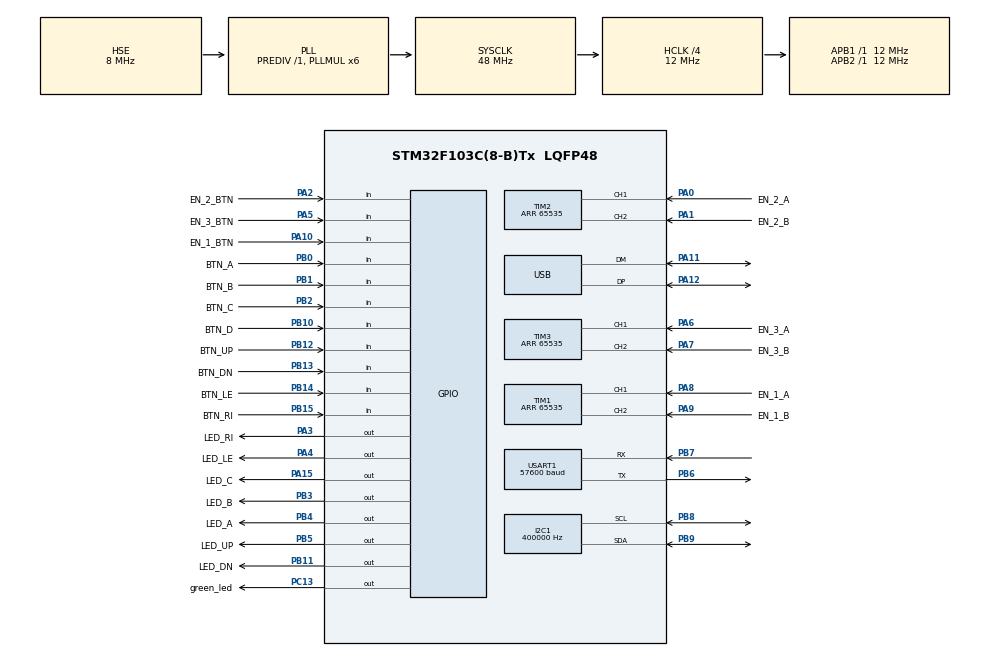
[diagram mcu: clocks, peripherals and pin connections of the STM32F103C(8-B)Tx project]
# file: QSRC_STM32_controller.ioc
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I2C1.ClockSpeed=400000
I2C1.DutyCycle=I2C_DUTYCYCLE_2
I2C1.I2C_Mode=I2C_Fast
Mcu.Family=STM32F1
Mcu.Name=STM32F103C(8-B)Tx
Mcu.Package=LQFP48
NVIC.PriorityGroup=NVIC_PRIORITYGROUP_4
NVIC.RTC_IRQn=true\:0\:0\:false\:false\:true\:true\:true
NVIC.TIM4_IRQn=true\:0\:0\:false\:false\:true\:true\:true
NVIC.USART1_IRQn=true\:0\:0\:false\:false\:true\:true\:true
NVIC.USB_LP_CAN1_RX0_IRQn=true\:0\:0\:false\:false\:true\:true\:true
PA0-WKUP.GPIO_Label=EN_2_A
PA0-WKUP.GPIO_PuPd=GPIO_PULLUP
PA0-WKUP.Signal=S_TIM2_CH1_ETR
PA1.GPIO_Label=EN_2_B
PA1.GPIO_PuPd=GPIO_PULLUP
PA1.Signal=S_TIM2_CH2
PA10.GPIO_Label=EN_1_BTN
PA10.GPIO_PuPd=GPIO_PULLUP
PA10.Signal=GPIO_Input
PA11.Mode=Device
PA11.Signal=USB_DM
PA12.Mode=Device
PA12.Signal=USB_DP
PA13.Mode=Serial_Wire
PA13.Signal=SYS_JTMS-SWDIO
PA14.Mode=Serial_Wire
PA14.Signal=SYS_JTCK-SWCLK
PA15.GPIO_Label=LED_C
PA15.Signal=GPIO_Output
PA2.GPIO_Label=EN_2_BTN
PA2.GPIO_PuPd=GPIO_PULLUP
PA2.Signal=GPIO_Input
PA3.GPIO_Label=LED_RI
PA3.PinState=GPIO_PIN_RESET
PA3.Signal=GPIO_Output
PA4.GPIO_Label=LED_LE
PA4.Signal=GPIO_Output
PA5.GPIO_Label=EN_3_BTN
PA5.GPIO_PuPd=GPIO_PULLUP
PA5.Signal=GPIO_Input
PA6.GPIO_Label=EN_3_A
PA6.GPIO_PuPd=GPIO_PULLUP
PA6.Signal=S_TIM3_CH1
PA7.GPIO_Label=EN_3_B
PA7.GPIO_PuPd=GPIO_PULLUP
PA7.Signal=S_TIM3_CH2
PA8.GPIO_Label=EN_1_A
PA8.GPIO_PuPd=GPIO_PULLUP
PA8.Signal=S_TIM1_CH1
PA9.GPIO_Label=EN_1_B
PA9.GPIO_PuPd=GPIO_PULLUP
PA9.Signal=S_TIM1_CH2
PB0.GPIO_Label=BTN_A
PB0.GPIO_PuPd=GPIO_PULLUP
PB0.Signal=GPIO_Input
PB1.GPIO_Label=BTN_B
PB1.GPIO_PuPd=GPIO_PULLUP
PB1.Signal=GPIO_Input
PB10.GPIO_Label=BTN_D
PB10.GPIO_PuPd=GPIO_PULLUP
PB10.Signal=GPIO_Input
PB11.GPIO_Label=LED_DN
PB11.Signal=GPIO_Output
PB12.GPIO_Label=BTN_UP
PB12.GPIO_PuPd=GPIO_PULLUP
PB12.Signal=GPIO_Input
PB13.GPIO_Label=BTN_DN
PB13.GPIO_PuPd=GPIO_PULLUP
PB13.Signal=GPIO_Input
PB14.GPIO_Label=BTN_LE
PB14.GPIO_PuPd=GPIO_PULLUP
PB14.Signal=GPIO_Input
PB15.GPIO_Label=BTN_RI
PB15.GPIO_PuPd=GPIO_PULLUP
PB15.Signal=GPIO_Input
PB2.GPIO_Label=BTN_C
PB2.GPIO_PuPd=GPIO_PULLUP
PB2.Signal=GPIO_Input
PB3.GPIO_Label=LED_B
PB3.Signal=GPIO_Output
PB4.GPIO_Label=LED_A
PB4.Signal=GPIO_Output
PB5.GPIO_Label=LED_UP
PB5.Signal=GPIO_Output
PB6.Mode=Asynchronous
PB6.Signal=USART1_TX
PB7.Mode=Asynchronous
PB7.Signal=USART1_RX
PB8.Mode=I2C
PB8.Signal=I2C1_SCL
PB9.Mode=I2C
PB9.Signal=I2C1_SDA
PC13-TAMPER-RTC.GPIO_Label=green_led
PC13-TAMPER-RTC.GPIO_Speed=GPIO_SPEED_FREQ_LOW
PC13-TAMPER-RTC.PinState=GPIO_PIN_SET
PC13-TAMPER-RTC.Signal=GPIO_Output
PC14-OSC32_IN.Mode=LSE-External-Oscillator
PC14-OSC32_IN.Signal=RCC_OSC32_IN
PC15-OSC32_OUT.Mode=LSE-External-Oscillator
PC15-OSC32_OUT.Signal=RCC_OSC32_OUT
PD0-OSC_IN.Mode=HSE-External-Oscillator
PD0-OSC_IN.Signal=RCC_OSC_IN
PD1-OSC_OUT.Mode=HSE-External-Oscillator
PD1-OSC_OUT.Signal=RCC_OSC_OUT
ProjectManager.HeapSize=0x200
ProjectManager.StackSize=0x400
ProjectManager.TargetToolchain=STM32CubeIDE
RCC.AHBCLKDivider=RCC_SYSCLK_DIV4
RCC.AHBFreq_Value=12000000
RCC.APB1Freq_Value=12000000
RCC.APB1TimFreq_Value=12000000
RCC.APB2Freq_Value=12000000
RCC.APB2TimFreq_Value=12000000
RCC.HCLKFreq_Value=12000000
RCC.PLLMUL=RCC_PLL_MUL6
RCC.SYSCLKFreq_VALUE=48000000
RCC.SYSCLKSource=RCC_SYSCLKSOURCE_PLLCLK
RCC.USBFreq_Value=48000000
SH.S_TIM1_CH1.0=TIM1_CH1,Encoder_Interface
SH.S_TIM1_CH2.0=TIM1_CH2,Encoder_Interface
SH.S_TIM2_CH1_ETR.0=TIM2_CH1,Encoder_Interface
SH.S_TIM2_CH2.0=TIM2_CH2,Encoder_Interface
SH.S_TIM3_CH1.0=TIM3_CH1,Encoder_Interface
SH.S_TIM3_CH2.0=TIM3_CH2,Encoder_Interface
TIM1.CounterMode=TIM_COUNTERMODE_DOWN
TIM1.EncoderMode=TIM_ENCODERMODE_TI12
TIM1.IC1Filter=15
TIM1.IC1Polarity=TIM_ICPOLARITY_FALLING
TIM1.IC2Filter=15
TIM1.Period=65535
TIM2.CounterMode=TIM_COUNTERMODE_DOWN
TIM2.EncoderMode=TIM_ENCODERMODE_TI12
TIM2.IC1Filter=15
TIM2.IC1Polarity=TIM_ICPOLARITY_FALLING
TIM2.IC2Filter=15
TIM2.Period=65535
TIM3.CounterMode=TIM_COUNTERMODE_DOWN
TIM3.EncoderMode=TIM_ENCODERMODE_TI12
TIM3.IC1Filter=15
TIM3.IC1Polarity=TIM_ICPOLARITY_FALLING
TIM3.IC2Filter=15
TIM3.IC2Polarity=TIM_ICPOLARITY_FALLING
TIM3.Period=65535
USART1.BaudRate=57600
USART1.VirtualMode=VM_ASYNC
USB_DEVICE.CLASS_NAME_FS=CDC
USB_DEVICE.PRODUCT_STRING_CDC_FS=QSRC
USB_DEVICE.SERIALNUMBER_STRING_CDC_FS=1A
USB_DEVICE.USBD_SUPPORT_USER_STRING-CDC_FS=0
USB_DEVICE.VirtualMode=Cdc
USB_DEVICE.VirtualModeFS=Cdc_FS
VP_RTC_No_RTC_Output.Mode=RTC_OUT_NO
VP_RTC_VS_RTC_Activate.Mode=RTC_Enabled
VP_TIM4_VS_ClockSourceINT.Mode=Internal
VP_USB_DEVICE_VS_USB_DEVICE_CDC_FS.Mode=CDC_FS
board=QSRC_STM32_controller

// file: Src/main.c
/* USER CODE BEGIN Header */
/**
  ******************************************************************************
  * @file           : main.c
  * @brief          : Main program body
  ******************************************************************************
  * @attention
  *
  * <h2><center>&copy; Copyright (c) 2022 STMicroelectronics.
  * All rights reserved.</center></h2>
  *
  * This software component is licensed by ST under Ultimate Liberty license
  * SLA0044, the "License"; You may not use this file except in compliance with
  * the License. You may obtain a copy of the License at:
  *                             www.st.com/SLA0044
  *
  ******************************************************************************
  */
/* USER CODE END Header */

#include "main.h"
#include "i2c.h"
#include "rtc.h"
#include "tim.h"
#include "usart.h"
#include "usb_device.h"
#include "gpio.h"

/* USER CODE BEGIN Includes */
#include "startup.h"
/* USER CODE END Includes */

/* USER CODE BEGIN PV */
/* Private variables ---------------------------------------------------------*/

/* USER CODE END PV */

void SystemClock_Config(void);
/* USER CODE BEGIN PFP */
/* Private function prototypes -----------------------------------------------*/

/* USER CODE END PFP */

int main(void)
{

  /* MCU Configuration--------------------------------------------------------*/

  /* Reset of all peripherals, Initializes the Flash interface and the Systick. */
  HAL_Init();

  /* Configure the system clock */
  SystemClock_Config();

  /* Initialize all configured peripherals */
  MX_GPIO_Init();
  MX_I2C1_Init();
  MX_RTC_Init();
  MX_TIM1_Init();
  MX_TIM2_Init();
  MX_TIM3_Init();
  MX_TIM4_Init();
  MX_USART1_UART_Init();
  MX_USB_DEVICE_Init();
  /* USER CODE BEGIN 2 */
  startup();
  /* USER CODE END 2 */

  /* Infinite loop */
  while (1)
  {

  }
}

void SystemClock_Config(void)
{
  RCC_OscInitTypeDef RCC_OscInitStruct = {0};
  RCC_ClkInitTypeDef RCC_ClkInitStruct = {0};
  RCC_PeriphCLKInitTypeDef PeriphClkInit = {0};

  /** Initializes the CPU, AHB and APB busses clocks
  */
  RCC_OscInitStruct.OscillatorType = RCC_OSCILLATORTYPE_LSI|RCC_OSCILLATORTYPE_HSE;
  RCC_OscInitStruct.HSEState = RCC_HSE_ON;
  RCC_OscInitStruct.HSEPredivValue = RCC_HSE_PREDIV_DIV1;
  RCC_OscInitStruct.HSIState = RCC_HSI_ON;
  RCC_OscInitStruct.LSIState = RCC_LSI_ON;
  RCC_OscInitStruct.PLL.PLLState = RCC_PLL_ON;
  RCC_OscInitStruct.PLL.PLLSource = RCC_PLLSOURCE_HSE;
  RCC_OscInitStruct.PLL.PLLMUL = RCC_PLL_MUL6;
  if (HAL_RCC_OscConfig(&RCC_OscInitStruct) != HAL_OK)
  {
    Error_Handler();
  }
  /** Initializes the CPU, AHB and APB busses clocks
  */
  RCC_ClkInitStruct.ClockType = RCC_CLOCKTYPE_HCLK|RCC_CLOCKTYPE_SYSCLK
                              |RCC_CLOCKTYPE_PCLK1|RCC_CLOCKTYPE_PCLK2;
  RCC_ClkInitStruct.SYSCLKSource = RCC_SYSCLKSOURCE_PLLCLK;
  RCC_ClkInitStruct.AHBCLKDivider = RCC_SYSCLK_DIV4;
  RCC_ClkInitStruct.APB1CLKDivider = RCC_HCLK_DIV1;
  RCC_ClkInitStruct.APB2CLKDivider = RCC_HCLK_DIV1;

  if (HAL_RCC_ClockConfig(&RCC_ClkInitStruct, FLASH_LATENCY_1) != HAL_OK)
  {
    Error_Handler();
  }
  PeriphClkInit.PeriphClockSelection = RCC_PERIPHCLK_RTC|RCC_PERIPHCLK_USB;
  PeriphClkInit.RTCClockSelection = RCC_RTCCLKSOURCE_LSI;
  PeriphClkInit.UsbClockSelection = RCC_USBCLKSOURCE_PLL;
  if (HAL_RCCEx_PeriphCLKConfig(&PeriphClkInit) != HAL_OK)
  {
    Error_Handler();
  }
}

void Error_Handler(void)
{
}

/************************ (C) COPYRIGHT STMicroelectronics *****END OF FILE****/
